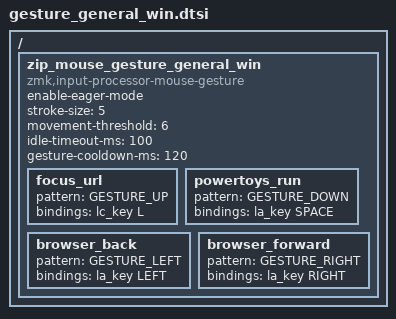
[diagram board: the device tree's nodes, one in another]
/ {
  zip_mouse_gesture_general_win: zip_mouse_gesture_general_win {
    compatible = "zmk,input-processor-mouse-gesture";
    #input-processor-cells = <0>;  
    enable-eager-mode;
    stroke-size = <5>;
    movement-threshold = <6>;
    idle-timeout-ms = <100>;
    gesture-cooldown-ms = <120>;

    focus_url        { pattern = <GESTURE_UP>;    bindings = <&lc_key L>;     };  // URLバー選択
    powertoys_run    { pattern = <GESTURE_DOWN>;  bindings = <&la_key SPACE>; };  // PowerToys Run
    browser_back     { pattern = <GESTURE_LEFT>;  bindings = <&la_key LEFT>;  };  // ブラウザ戻る
    browser_forward  { pattern = <GESTURE_RIGHT>; bindings = <&la_key RIGHT>; };  // ブラウザ進む
  };
};
